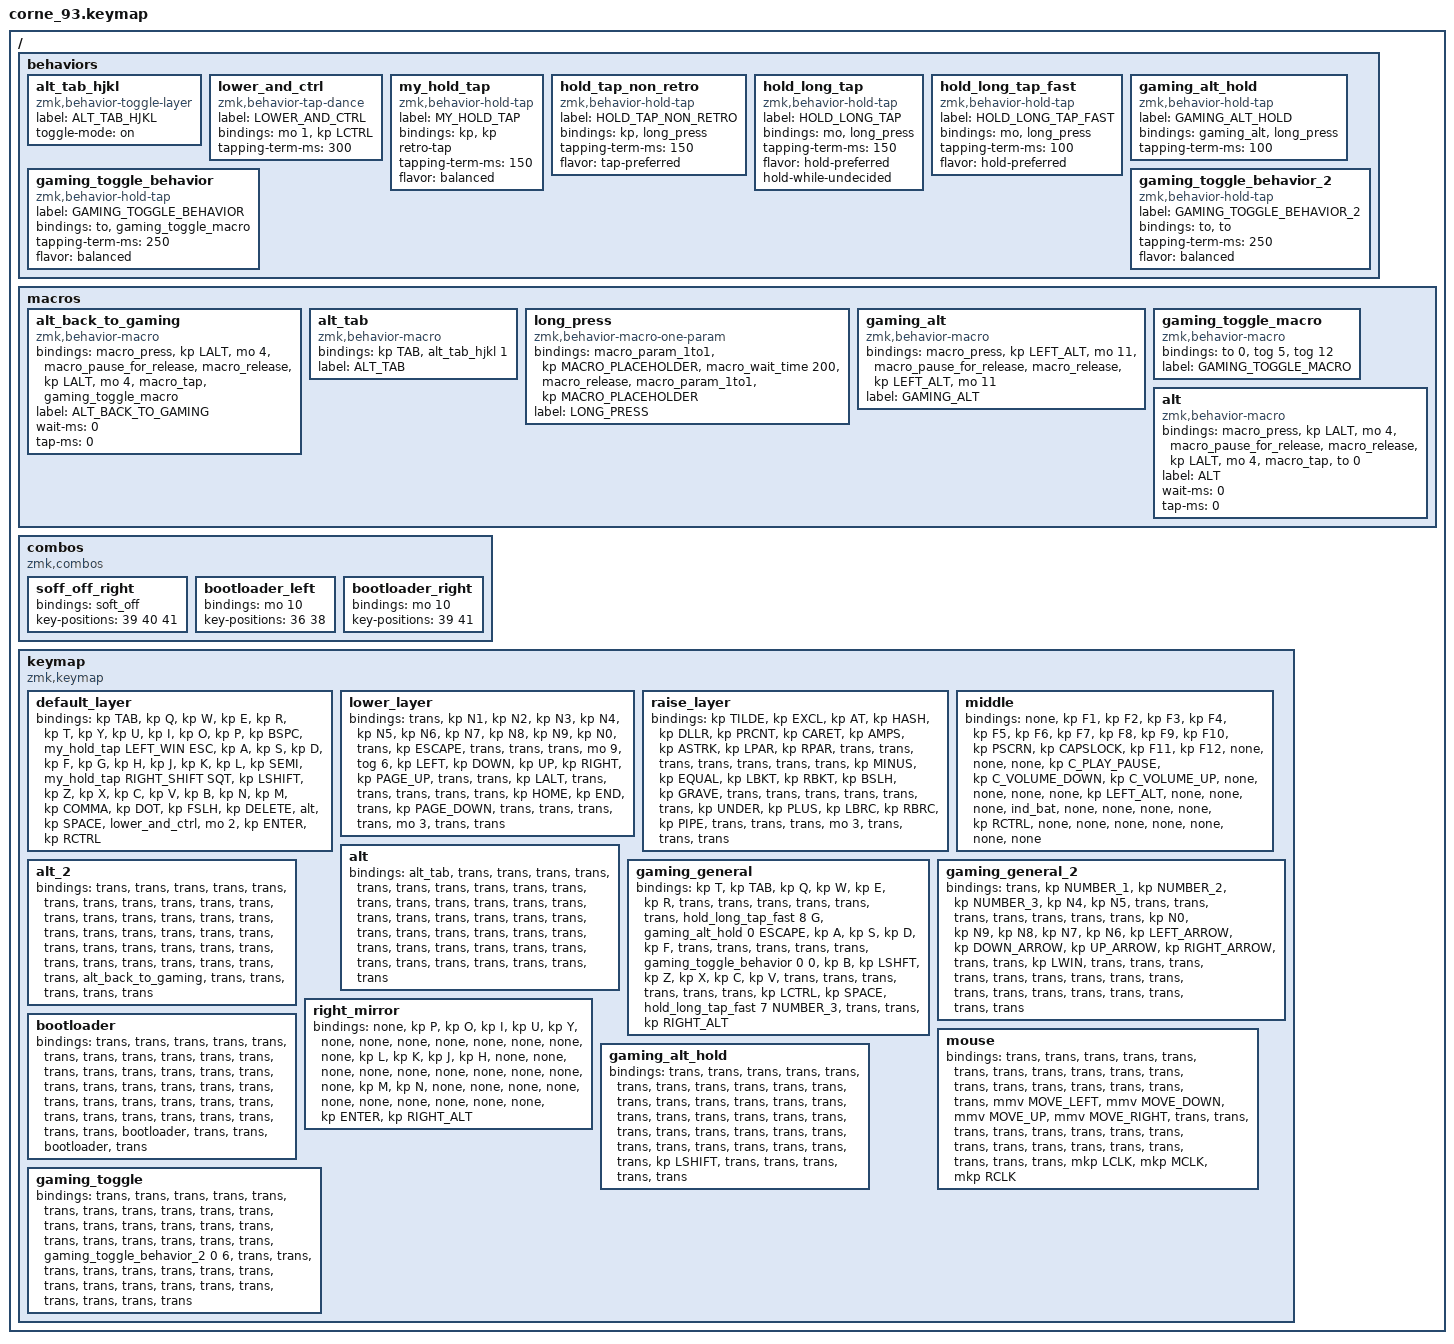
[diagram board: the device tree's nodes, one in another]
// This file was generated from a template. Edit it to match your keyboard.
// See https://zmk.dev/docs/development/hardware-integration/new-shield for more instructions.

#include <behaviors/rgbled_widget.dtsi>
#include <behaviors.dtsi>
#include <dt-bindings/zmk/keys.h>
#include <dt-bindings/zmk/pointing.h>

/ {
    // Define a default keymap here.
    // See https://zmk.dev/docs/development/hardware-integration/new-shield#default-keymap.
    //

    behaviors {
        alt_tab_hjkl: alt_tab_hjkl {
            compatible = "zmk,behavior-toggle-layer";
            label = "ALT_TAB_HJKL";
            #binding-cells = <1>;
            toggle-mode = "on";
        };

        lower_and_ctrl: lower_and_ctrl {
            compatible = "zmk,behavior-tap-dance";
            label = "LOWER_AND_CTRL";
            #binding-cells = <0>;
            bindings = <&mo 1>, <&kp LCTRL>;

            tapping-term-ms = <300>;
        };

        my_hold_tap: my_hold_tap {
            compatible = "zmk,behavior-hold-tap";
            label = "MY_HOLD_TAP";
            bindings = <&kp>, <&kp>;

            #binding-cells = <2>;
            retro-tap;
            tapping-term-ms = <150>;
            flavor = "balanced";
        };

        hold_tap_non_retro: hold_tap_non_retro {
            compatible = "zmk,behavior-hold-tap";
            label = "HOLD_TAP_NON_RETRO";
            bindings = <&kp>, <&long_press>;

            #binding-cells = <2>;
            tapping-term-ms = <150>;
            flavor = "tap-preferred";
        };

        hold_long_tap: hold_long_tap {
            compatible = "zmk,behavior-hold-tap";
            label = "HOLD_LONG_TAP";
            bindings = <&mo>, <&long_press>;

            #binding-cells = <2>;
            tapping-term-ms = <150>;
            flavor = "hold-preferred";
            hold-while-undecided;
        };

        hold_long_tap_fast: hold_long_tap_fast {
            compatible = "zmk,behavior-hold-tap";
            label = "HOLD_LONG_TAP_FAST";
            bindings = <&mo>, <&long_press>;

            #binding-cells = <2>;
            tapping-term-ms = <100>;
            flavor = "hold-preferred";
        };

        gaming_alt_hold: gaming_alt_hold {
            compatible = "zmk,behavior-hold-tap";
            label = "GAMING_ALT_HOLD";
            bindings = <&gaming_alt>, <&long_press>;

            #binding-cells = <2>;
            tapping-term-ms = <100>;
        };

        gaming_toggle_behavior: gaming_toggle_behavior {
            compatible = "zmk,behavior-hold-tap";
            label = "GAMING_TOGGLE_BEHAVIOR";
            bindings = <&to>, <&gaming_toggle_macro>;

            #binding-cells = <2>;
            tapping-term-ms = <250>;
            flavor = "balanced";
        };

        gaming_toggle_behavior_2: gaming_toggle_behavior_2 {
            compatible = "zmk,behavior-hold-tap";
            label = "GAMING_TOGGLE_BEHAVIOR_2";
            bindings = <&to>, <&to>;

            #binding-cells = <2>;
            tapping-term-ms = <250>;
            flavor = "balanced";
        };
    };

    macros {
        alt_back_to_gaming: alt_back_to_gaming {
            compatible = "zmk,behavior-macro";
            #binding-cells = <0>;
            bindings =
                <&macro_press>,
                <&kp LALT &mo 4>,
                <&macro_pause_for_release>,
                <&macro_release>,
                <&kp LALT &mo 4>,
                <&macro_tap>,
                <&gaming_toggle_macro>;

            label = "ALT_BACK_TO_GAMING";
            wait-ms = <0>;
            tap-ms = <0>;
        };

        alt_tab: alt_tab {
            compatible = "zmk,behavior-macro";
            #binding-cells = <0>;
            bindings = <&kp TAB &alt_tab_hjkl 1>;
            label = "ALT_TAB";
        };

        long_press: long_press {
            compatible = "zmk,behavior-macro-one-param";
            #binding-cells = <1>;
            bindings =
                <&macro_param_1to1 &kp MACRO_PLACEHOLDER>,
                <&macro_wait_time 200>,
                <&macro_release>,
                <&macro_param_1to1 &kp MACRO_PLACEHOLDER>;

            label = "LONG_PRESS";
        };

        gaming_alt: gaming_alt {
            compatible = "zmk,behavior-macro";
            #binding-cells = <0>;
            bindings =
                <&macro_press>,
                <&kp LEFT_ALT &mo 11>,
                <&macro_pause_for_release>,
                <&macro_release>,
                <&kp LEFT_ALT &mo 11>;

            label = "GAMING_ALT";
        };

        gaming_toggle_macro: gaming_toggle_macro {
            compatible = "zmk,behavior-macro";
            #binding-cells = <0>;
            bindings = <&to 0 &tog 5 &tog 12>;
            label = "GAMING_TOGGLE_MACRO";
        };

        alt: alt {
            compatible = "zmk,behavior-macro";
            #binding-cells = <0>;
            bindings =
                <&macro_press>,
                <&kp LALT &mo 4>,
                <&macro_pause_for_release>,
                <&macro_release>,
                <&kp LALT &mo 4>,
                <&macro_tap>,
                <&to 0>;

            label = "ALT";
            wait-ms = <0>;
            tap-ms = <0>;
        };
    };

    combos {
        compatible = "zmk,combos";

        soff_off_right {
            bindings = <&soft_off>;
            key-positions = <39 40 41>;
        };

        bootloader_left {
            bindings = <&mo 10>;
            key-positions = <36 38>;
        };

        bootloader_right {
            bindings = <&mo 10>;
            key-positions = <39 41>;
        };
    };

    keymap {
        compatible = "zmk,keymap";

        default_layer {
            bindings = <
&kp TAB  &kp Q  &kp W  &kp E  &kp R  &kp T  &kp Y  &kp U  &kp I  &kp O  &kp P  &kp BSPC  &my_hold_tap LEFT_WIN ESC  &kp A  &kp S  &kp D  &kp F  &kp G  &kp H  &kp J  &kp K  &kp L  &kp SEMI  &my_hold_tap RIGHT_SHIFT SQT  &kp LSHIFT  &kp Z  &kp X  &kp C  &kp V  &kp B  &kp N  &kp M  &kp COMMA  &kp DOT  &kp FSLH  &kp DELETE  &alt  &kp SPACE  &lower_and_ctrl  &mo 2  &kp ENTER  &kp RCTRL
            >;
        };

        lower_layer {
            bindings = <
&trans  &kp N1  &kp N2  &kp N3  &kp N4  &kp N5  &kp N6  &kp N7  &kp N8  &kp N9  &kp N0  &trans  &kp ESCAPE  &trans  &trans  &trans  &mo 9  &tog 6  &kp LEFT  &kp DOWN  &kp UP  &kp RIGHT  &kp PAGE_UP  &trans  &trans  &kp LALT  &trans  &trans  &trans  &trans  &trans  &kp HOME  &kp END  &trans  &kp PAGE_DOWN  &trans  &trans  &trans  &trans  &mo 3  &trans  &trans
            >;
        };

        raise_layer {
            bindings = <
&kp TILDE  &kp EXCL  &kp AT  &kp HASH  &kp DLLR  &kp PRCNT  &kp CARET  &kp AMPS  &kp ASTRK  &kp LPAR  &kp RPAR  &trans  &trans  &trans  &trans  &trans  &trans  &trans  &kp MINUS  &kp EQUAL  &kp LBKT  &kp RBKT  &kp BSLH  &kp GRAVE  &trans  &trans  &trans  &trans  &trans  &trans  &kp UNDER  &kp PLUS  &kp LBRC  &kp RBRC  &kp PIPE  &trans  &trans  &trans  &mo 3  &trans  &trans  &trans
            >;
        };

        middle {
            bindings = <
&none  &kp F1  &kp F2  &kp F3  &kp F4  &kp F5  &kp F6  &kp F7  &kp F8  &kp F9  &kp F10  &kp PSCRN  &kp CAPSLOCK  &kp F11  &kp F12  &none  &none  &none  &kp C_PLAY_PAUSE  &kp C_VOLUME_DOWN  &kp C_VOLUME_UP  &none  &none  &none  &none  &kp LEFT_ALT  &none  &none  &none  &ind_bat  &none  &none  &none  &none  &kp RCTRL  &none  &none  &none  &none  &none  &none  &none
            >;
        };

        alt {
            bindings = <
&alt_tab  &trans  &trans  &trans  &trans  &trans  &trans  &trans  &trans  &trans  &trans  &trans  &trans  &trans  &trans  &trans  &trans  &trans  &trans  &trans  &trans  &trans  &trans  &trans  &trans  &trans  &trans  &trans  &trans  &trans  &trans  &trans  &trans  &trans  &trans  &trans  &trans  &trans  &trans  &trans  &trans  &trans
            >;
        };

        alt_2 {
            bindings = <
&trans  &trans  &trans  &trans  &trans  &trans  &trans  &trans  &trans  &trans  &trans  &trans  &trans  &trans  &trans  &trans  &trans  &trans  &trans  &trans  &trans  &trans  &trans  &trans  &trans  &trans  &trans  &trans  &trans  &trans  &trans  &trans  &trans  &trans  &trans  &trans  &alt_back_to_gaming  &trans  &trans  &trans  &trans  &trans
            >;
        };

        gaming_general {
            bindings = <
&kp T  &kp TAB  &kp Q  &kp W  &kp E  &kp R  &trans  &trans  &trans  &trans  &trans  &trans  &hold_long_tap_fast 8 G  &gaming_alt_hold 0 ESCAPE  &kp A  &kp S  &kp D  &kp F  &trans  &trans  &trans  &trans  &trans  &gaming_toggle_behavior 0 0  &kp B  &kp LSHFT  &kp Z  &kp X  &kp C  &kp V  &trans  &trans  &trans  &trans  &trans  &trans  &kp LCTRL  &kp SPACE  &hold_long_tap_fast 7 NUMBER_3  &trans  &trans  &kp RIGHT_ALT
            >;
        };

        gaming_general_2 {
            bindings = <
&trans  &kp NUMBER_1  &kp NUMBER_2  &kp NUMBER_3  &kp N4  &kp N5  &trans  &trans  &trans  &trans  &trans  &trans  &trans  &kp N0  &kp N9  &kp N8  &kp N7  &kp N6  &kp LEFT_ARROW  &kp DOWN_ARROW  &kp UP_ARROW  &kp RIGHT_ARROW  &trans  &trans  &kp LWIN  &trans  &trans  &trans  &trans  &trans  &trans  &trans  &trans  &trans  &trans  &trans  &trans  &trans  &trans  &trans  &trans  &trans
            >;
        };

        right_mirror {
            bindings = <
&none  &kp P  &kp O  &kp I  &kp U  &kp Y  &none  &none  &none  &none  &none  &none  &none  &none  &kp L  &kp K  &kp J  &kp H  &none  &none  &none  &none  &none  &none  &none  &none  &none  &none  &kp M  &kp N  &none  &none  &none  &none  &none  &none  &none  &none  &none  &none  &kp ENTER  &kp RIGHT_ALT
            >;
        };

        mouse {
            bindings = <
&trans  &trans  &trans  &trans  &trans  &trans  &trans  &trans  &trans  &trans  &trans  &trans  &trans  &trans  &trans  &trans  &trans  &trans  &mmv MOVE_LEFT  &mmv MOVE_DOWN  &mmv MOVE_UP  &mmv MOVE_RIGHT  &trans  &trans  &trans  &trans  &trans  &trans  &trans  &trans  &trans  &trans  &trans  &trans  &trans  &trans  &trans  &trans  &trans  &mkp LCLK  &mkp MCLK  &mkp RCLK
            >;
        };

        bootloader {
            bindings = <
&trans  &trans  &trans  &trans  &trans  &trans  &trans  &trans  &trans  &trans  &trans  &trans  &trans  &trans  &trans  &trans  &trans  &trans  &trans  &trans  &trans  &trans  &trans  &trans  &trans  &trans  &trans  &trans  &trans  &trans  &trans  &trans  &trans  &trans  &trans  &trans  &trans  &bootloader  &trans  &trans  &bootloader  &trans
            >;
        };

        gaming_alt_hold {
            bindings = <
&trans  &trans  &trans  &trans  &trans  &trans  &trans  &trans  &trans  &trans  &trans  &trans  &trans  &trans  &trans  &trans  &trans  &trans  &trans  &trans  &trans  &trans  &trans  &trans  &trans  &trans  &trans  &trans  &trans  &trans  &trans  &trans  &trans  &trans  &trans  &trans  &kp LSHIFT  &trans  &trans  &trans  &trans  &trans
            >;
        };

        gaming_toggle {
            bindings = <
&trans  &trans  &trans  &trans  &trans  &trans  &trans  &trans  &trans  &trans  &trans  &trans  &trans  &trans  &trans  &trans  &trans  &trans  &trans  &trans  &trans  &trans  &trans  &gaming_toggle_behavior_2 0 6  &trans  &trans  &trans  &trans  &trans  &trans  &trans  &trans  &trans  &trans  &trans  &trans  &trans  &trans  &trans  &trans  &trans  &trans
            >;
        };
    };
};
